AUTOSAR XML (schema 4-0-3)
package /ComponentTypes
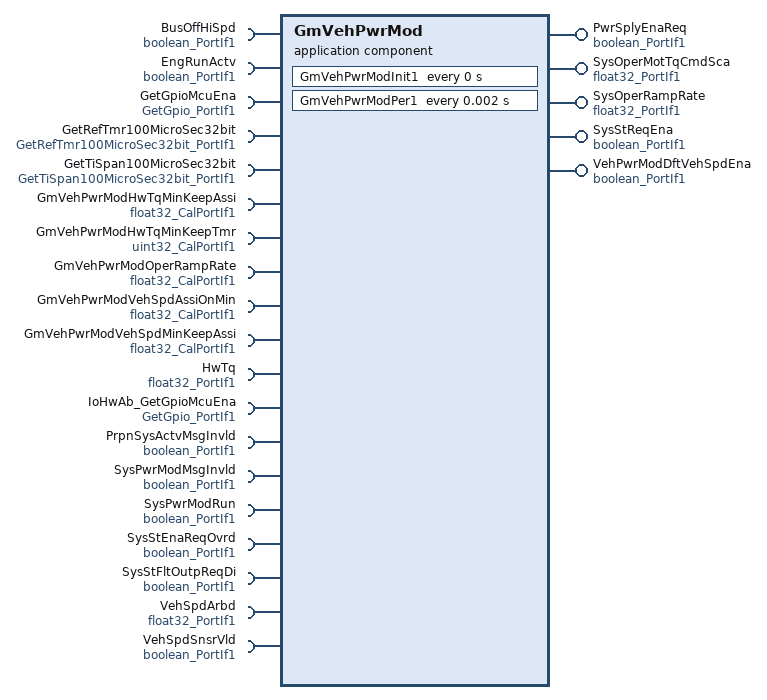
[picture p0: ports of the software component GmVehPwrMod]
  application sw component type GmVehPwrMod
    5 x provide port:
      PwrSplyEnaReq: nonqueued-sender-com-spec{data-element=Logl, init-value=0}, provided-interface=boolean_PortIf1
      SysOperMotTqCmdSca: nonqueued-sender-com-spec{data-element=Val, init-value=1}, provided-interface=float32_PortIf1
      SysOperRampRate: nonqueued-sender-com-spec{data-element=Val, init-value=1}, provided-interface=float32_PortIf1
      SysStReqEna: nonqueued-sender-com-spec{data-element=Logl, init-value=0}, provided-interface=boolean_PortIf1
      VehPwrModDftVehSpdEna: nonqueued-sender-com-spec{data-element=Logl, init-value=0}, provided-interface=boolean_PortIf1
    19 x require port:
      BusOffHiSpd: nonqueued-receiver-com-spec{data-element=Logl, filter=data-filter-type=ALWAYS, init-value=0}, required-interface=boolean_PortIf1
      EngRunActv: nonqueued-receiver-com-spec{data-element=Logl, filter=data-filter-type=ALWAYS, init-value=0}, required-interface=boolean_PortIf1
      GetGpioMcuEna: required-interface=GetGpio_PortIf1
      GetRefTmr100MicroSec32bit: required-interface=GetRefTmr100MicroSec32bit_PortIf1
      GetTiSpan100MicroSec32bit: required-interface=GetTiSpan100MicroSec32bit_PortIf1
      GmVehPwrModHwTqMinKeepAssi: parameter-require-com-spec{init-value=0.8, parameter=Val}, required-interface=float32_CalPortIf1
      GmVehPwrModHwTqMinKeepTmr: parameter-require-com-spec{init-value=10, parameter=Val}, required-interface=uint32_CalPortIf1
      GmVehPwrModOperRampRate: parameter-require-com-spec{init-value=0.5, parameter=Val}, required-interface=float32_CalPortIf1
      GmVehPwrModVehSpdAssiOnMin: parameter-require-com-spec{init-value=0.1, parameter=Val}, required-interface=float32_CalPortIf1
      GmVehPwrModVehSpdMinKeepAssi: parameter-require-com-spec{init-value=3, parameter=Val}, required-interface=float32_CalPortIf1
      HwTq: nonqueued-receiver-com-spec{data-element=Val, filter=data-filter-type=ALWAYS, init-value=0}, required-interface=float32_PortIf1
      IoHwAb_GetGpioMcuEna: required-interface=GetGpio_PortIf1
      PrpnSysActvMsgInvld: nonqueued-receiver-com-spec{data-element=Logl, filter=data-filter-type=ALWAYS, init-value=0}, required-interface=boolean_PortIf1
      SysPwrModMsgInvld: nonqueued-receiver-com-spec{data-element=Logl, filter=data-filter-type=ALWAYS, init-value=0}, required-interface=boolean_PortIf1
      SysPwrModRun: nonqueued-receiver-com-spec{data-element=Logl, filter=data-filter-type=ALWAYS, init-value=0}, required-interface=boolean_PortIf1
      SysStEnaReqOvrd: nonqueued-receiver-com-spec{data-element=Logl, filter=data-filter-type=ALWAYS, init-value=0}, required-interface=boolean_PortIf1
      SysStFltOutpReqDi: nonqueued-receiver-com-spec{data-element=Logl, filter=data-filter-type=ALWAYS, init-value=0}, required-interface=boolean_PortIf1
      VehSpdArbd: nonqueued-receiver-com-spec{data-element=Val, filter=data-filter-type=ALWAYS, init-value=0}, required-interface=float32_PortIf1
      VehSpdSnsrVld: nonqueued-receiver-com-spec{data-element=Logl, filter=data-filter-type=ALWAYS, init-value=0}, required-interface=boolean_PortIf1
    behavior GmVehPwrMod_InternalBehavior
      ar-typed-per-instance-memorys:
        6 x data, all with sw-calibration-access=READ-ONLY:
          dGmVehPwrModHwTqKeepAssi: type=boolean
          dGmVehPwrModVehSpdAssiKeepMin: type=boolean
          dGmVehPwrModVehSpdAssiOnMin: type=boolean
          PrevSysStReqEnaVal: type=boolean
          TqRefTi: type=uint32
          TqRefTiActv: type=boolean
      timing event GmVehPwrMod_InitEvent: start-on-event=GmVehPwrModInit1, period=0
      timing event TMT_GmVehPwrModPer1: start-on-event=GmVehPwrModPer1, period=0.002
      runnable GmVehPwrModInit1
      runnable GmVehPwrModPer1
        data-receive-point-by-arguments:
          10 x access:
            REC_BusOffHiSpd_Logl: accessed-variable=BusOffHiSpd.Logl
            REC_EngRunActv_Logl: accessed-variable=EngRunActv.Logl
            REC_HwTq_Val: accessed-variable=HwTq.Val
            REC_Msg0C9Miss_Logl: accessed-variable=PrpnSysActvMsgInvld.Logl
            REC_Msg1F1Miss_Logl: accessed-variable=SysPwrModMsgInvld.Logl
            REC_SysPwrModRun_Logl: accessed-variable=SysPwrModRun.Logl
            REC_SysStEnaReqOvrd_Logl: accessed-variable=SysStEnaReqOvrd.Logl
            REC_SysStFltOutpReqDi_Logl: accessed-variable=SysStFltOutpReqDi.Logl
            REC_VehSpdArbd_Val: accessed-variable=VehSpdArbd.Val
            REC_VehSpdSnsrVld_Logl: accessed-variable=VehSpdSnsrVld.Logl
        data-send-points:
          5 x access:
            SEND_PwrSplyEnaReq_Logl: accessed-variable=PwrSplyEnaReq.Logl
            SEND_SysOperMotTqCmdSca_Val: accessed-variable=SysOperMotTqCmdSca.Val
            SEND_SysOperRampRate_Val: accessed-variable=SysOperRampRate.Val
            SEND_SysStReqEna_Logl: accessed-variable=SysStReqEna.Logl
            SEND_VehPwrModDftVehSpdEna_Logl: accessed-variable=VehPwrModDftVehSpdEna.Logl
        sync call SC_GetGpioMcuEna_Oper: operation=GetGpioMcuEna.Oper, timeout=0
        sync call SC_GetRefTmr100MicroSec32bit_Oper: operation=GetRefTmr100MicroSec32bit.Oper, timeout=0
        sync call SC_GetTiSpan100MicroSec32bit_Oper: operation=GetTiSpan100MicroSec32bit.Oper, timeout=0
  swc implementation GmVehPwrMod_Implementation: behavior=GmVehPwrMod_InternalBehavior
    code-descriptors:
      code Default: artifact-descriptors=autosar-engineering-object={short-label=Default, category=SWSRC}
